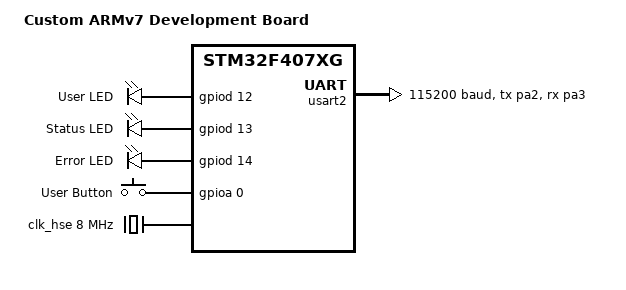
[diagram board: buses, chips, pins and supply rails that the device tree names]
/*
 * SPDX-License-Identifier: Apache-2.0
 *
 * Device Tree Source for Custom ARMv7 Board
 *
 * This is an out-of-tree board definition based on STM32F407VG MCU
 * demonstrating custom hardware configuration for Zephyr RTOS.
 */

/dts-v1/;
#include <st/f4/stm32f407Xg.dtsi>
#include <st/f4/stm32f407v(e-g)tx-pinctrl.dtsi>

/ {
	model = "Custom ARMv7 Development Board";
	compatible = "custom,armv7-board";

	/* Define which SRAM/Flash the firmware uses */
	chosen {
		zephyr,console = &usart2;
		zephyr,shell-uart = &usart2;
		zephyr,sram = &sram0;
		zephyr,flash = &flash0;
		zephyr,ccm = &ccm0;
	};

	/* On-board LEDs */
	leds {
		compatible = "gpio-leds";

		/* User LED on PD12 (directly mapped) */
		user_led: led_0 {
			gpios = <&gpiod 12 GPIO_ACTIVE_HIGH>;
			label = "User LED";
		};

		/* Status LED on PD13 */
		status_led: led_1 {
			gpios = <&gpiod 13 GPIO_ACTIVE_HIGH>;
			label = "Status LED";
		};

		/* Error LED on PD14 */
		error_led: led_2 {
			gpios = <&gpiod 14 GPIO_ACTIVE_HIGH>;
			label = "Error LED";
		};
	};

	/* On-board buttons */
	gpio_keys {
		compatible = "gpio-keys";

		/* User button on PA0 */
		user_button: button_0 {
			gpios = <&gpioa 0 (GPIO_PULL_DOWN | GPIO_ACTIVE_HIGH)>;
			label = "User Button";
			zephyr,code = <INPUT_KEY_0>;
		};
	};

	/* Define aliases for easy access */
	aliases {
		led0 = &user_led;
		led1 = &status_led;
		led2 = &error_led;
		sw0 = &user_button;
	};
};

/* Enable USART2 for console (PA2=TX, PA3=RX) */
&usart2 {
	pinctrl-0 = <&usart2_tx_pa2 &usart2_rx_pa3>;
	pinctrl-names = "default";
	current-speed = <115200>;
	status = "okay";
};

/* Enable GPIO ports used by LEDs and buttons */
&gpioa {
	status = "okay";
};

&gpiod {
	status = "okay";
};

/* Configure the main system clock */
&clk_hse {
	clock-frequency = <DT_FREQ_M(8)>;
	status = "okay";
};

&pll {
	div-m = <8>;
	mul-n = <336>;
	div-p = <2>;
	div-q = <7>;
	clocks = <&clk_hse>;
	status = "okay";
};

&rcc {
	clocks = <&pll>;
	clock-frequency = <DT_FREQ_M(168)>;
	ahb-prescaler = <1>;
	apb1-prescaler = <4>;
	apb2-prescaler = <2>;
};

/* Flash controller */
&flash0 {
	partitions {
		compatible = "fixed-partitions";
		#address-cells = <1>;
		#size-cells = <1>;

		/* Bootloader region */
		boot_partition: partition@0 {
			label = "bootloader";
			reg = <0x00000000 0x00010000>;
			read-only;
		};

		/* Main application slot */
		slot0_partition: partition@10000 {
			label = "image-0";
			reg = <0x00010000 0x00070000>;
		};

		/* Secondary application slot for OTA */
		slot1_partition: partition@80000 {
			label = "image-1";
			reg = <0x00080000 0x00070000>;
		};

		/* Storage partition */
		storage_partition: partition@f0000 {
			label = "storage";
			reg = <0x000f0000 0x00010000>;
		};
	};
};
